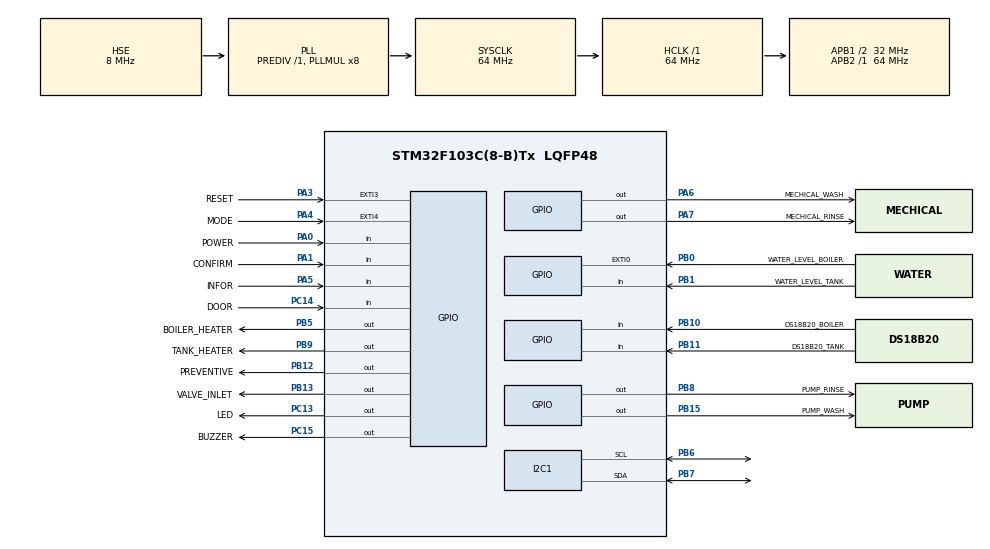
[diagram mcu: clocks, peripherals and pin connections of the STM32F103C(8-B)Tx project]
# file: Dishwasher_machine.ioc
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Mcu.Family=STM32F1
Mcu.Name=STM32F103C(8-B)Tx
Mcu.Package=LQFP48
NVIC.EXTI0_IRQn=true\:4\:0\:true\:false\:true\:true\:true\:true
NVIC.EXTI3_IRQn=true\:1\:0\:true\:false\:true\:true\:true\:true
NVIC.EXTI4_IRQn=true\:6\:0\:true\:false\:true\:true\:true\:true
NVIC.PriorityGroup=NVIC_PRIORITYGROUP_4
NVIC.TIM3_IRQn=true\:2\:0\:true\:false\:true\:true\:true\:true
PA0-WKUP.GPIO_Label=POWER
PA0-WKUP.GPIO_PuPd=GPIO_PULLUP
PA0-WKUP.Signal=GPIO_Input
PA1.GPIO_Label=CONFIRM
PA1.GPIO_PuPd=GPIO_PULLUP
PA1.Signal=GPIO_Input
PA13.Mode=Serial_Wire
PA13.Signal=SYS_JTMS-SWDIO
PA14.Mode=Serial_Wire
PA14.Signal=SYS_JTCK-SWCLK
PA3.GPIO_Label=RESET
PA3.GPIO_ModeDefaultEXTI=GPIO_MODE_IT_FALLING
PA3.GPIO_PuPd=GPIO_PULLUP
PA3.Signal=GPXTI3
PA4.GPIO_Label=MODE
PA4.GPIO_ModeDefaultEXTI=GPIO_MODE_IT_FALLING
PA4.GPIO_PuPd=GPIO_PULLUP
PA4.Signal=GPXTI4
PA5.GPIO_Label=INFOR
PA5.GPIO_PuPd=GPIO_PULLUP
PA5.Signal=GPIO_Input
PA6.GPIO_Label=MECHICAL_WASH
PA6.GPIO_PuPd=GPIO_PULLUP
PA6.Signal=GPIO_Output
PA7.GPIO_Label=MECHICAL_RINSE
PA7.GPIO_PuPd=GPIO_PULLUP
PA7.Signal=GPIO_Output
PB0.GPIO_Label=WATER_LEVEL_BOILER
PB0.GPIO_ModeDefaultEXTI=GPIO_MODE_IT_FALLING
PB0.GPIO_PuPd=GPIO_PULLUP
PB0.Signal=GPXTI0
PB1.GPIO_Label=WATER_LEVEL_TANK
PB1.GPIO_PuPd=GPIO_PULLUP
PB1.Signal=GPIO_Input
PB10.GPIO_Label=DS18B20_BOILER
PB10.GPIO_PuPd=GPIO_PULLUP
PB10.Signal=GPIO_Input
PB11.GPIO_Label=DS18B20_TANK
PB11.GPIO_PuPd=GPIO_PULLUP
PB11.Signal=GPIO_Input
PB12.GPIO_Label=PREVENTIVE
PB12.GPIO_PuPd=GPIO_PULLUP
PB12.PinState=GPIO_PIN_SET
PB12.Signal=GPIO_Output
PB13.GPIO_Label=VALVE_INLET
PB13.GPIO_PuPd=GPIO_PULLUP
PB13.PinState=GPIO_PIN_SET
PB13.Signal=GPIO_Output
PB15.GPIO_Label=PUMP_WASH
PB15.GPIO_PuPd=GPIO_PULLUP
PB15.PinState=GPIO_PIN_SET
PB15.Signal=GPIO_Output
PB5.GPIO_Label=BOILER_HEATER
PB5.GPIO_PuPd=GPIO_PULLUP
PB5.GPIO_Speed=GPIO_SPEED_FREQ_LOW
PB5.PinState=GPIO_PIN_SET
PB5.Signal=GPIO_Output
PB6.Mode=I2C
PB6.Signal=I2C1_SCL
PB7.Mode=I2C
PB7.Signal=I2C1_SDA
PB8.GPIO_Label=PUMP_RINSE
PB8.GPIO_PuPd=GPIO_PULLUP
PB8.GPIO_Speed=GPIO_SPEED_FREQ_LOW
PB8.PinState=GPIO_PIN_SET
PB8.Signal=GPIO_Output
PB9.GPIO_Label=TANK_HEATER
PB9.GPIO_PuPd=GPIO_PULLUP
PB9.PinState=GPIO_PIN_SET
PB9.Signal=GPIO_Output
PC13-TAMPER-RTC.GPIO_Label=LED
PC13-TAMPER-RTC.GPIO_PuPd=GPIO_PULLUP
PC13-TAMPER-RTC.PinState=GPIO_PIN_SET
PC13-TAMPER-RTC.Signal=GPIO_Output
PC14-OSC32_IN.GPIO_Label=DOOR
PC14-OSC32_IN.GPIO_PuPd=GPIO_PULLUP
PC14-OSC32_IN.Signal=GPIO_Input
PC15-OSC32_OUT.GPIO_Label=BUZZER
PC15-OSC32_OUT.GPIO_PuPd=GPIO_PULLUP
PC15-OSC32_OUT.Signal=GPIO_Output
PD0-OSC_IN.Mode=HSE-External-Oscillator
PD0-OSC_IN.Signal=RCC_OSC_IN
PD1-OSC_OUT.Mode=HSE-External-Oscillator
PD1-OSC_OUT.Signal=RCC_OSC_OUT
ProjectManager.HeapSize=0x200
ProjectManager.StackSize=0x400
ProjectManager.TargetToolchain=MDK-ARM V5.32
RCC.AHBFreq_Value=64000000
RCC.APB1CLKDivider=RCC_HCLK_DIV2
RCC.APB1Freq_Value=32000000
RCC.APB1TimFreq_Value=64000000
RCC.APB2Freq_Value=64000000
RCC.APB2TimFreq_Value=64000000
RCC.HCLKFreq_Value=64000000
RCC.PLLMUL=RCC_PLL_MUL8
RCC.PLLSourceVirtual=RCC_PLLSOURCE_HSE
RCC.SYSCLKFreq_VALUE=64000000
RCC.SYSCLKSource=RCC_SYSCLKSOURCE_PLLCLK
RCC.USBFreq_Value=64000000
TIM1.Period=65535-1
TIM1.Prescaler=64-1
TIM3.Period=2000-1
TIM3.Prescaler=64000-1
VP_TIM1_VS_ClockSourceINT.Mode=Internal
VP_TIM3_VS_ClockSourceINT.Mode=Internal
board=custom

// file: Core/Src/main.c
/* USER CODE BEGIN Header */
/* USER CODE END Header */
#include "main.h"

/* USER CODE BEGIN Includes */
#include "i2c-lcd.h"
#include "stdio.h"
#include "Funtion.h"

/* USER CODE END Includes */

I2C_HandleTypeDef hi2c1;
TIM_HandleTypeDef htim1;
TIM_HandleTypeDef htim3;
uint8_t 		power_press =0;
float 	volatile 	Temperature_boiler;
float 	volatile 	Temperature_tank = 0;
uint8_t 	volatile 	Presence = 0;
uint8_t 	volatile 	Temp_byte1, Temp_byte2;
uint16_t volatile 	TEMP;
uint8_t 	volatile 	BOILER_FULL=0;
uint8_t 	volatile 	TANK_FULL=0;
uint8_t 	volatile 	DOOR =1;
uint8_t 	volatile 	MODE =0;
uint8_t 	const 	Temp_Std_Wash =20;
uint8_t 	const 	Temp_Std_Rinse =20;
uint8_t 	const 	Temperature_max =100;
uint8_t count =0;
uint8_t a=0;

void SystemClock_Config(void);
static void MX_GPIO_Init(void);
static void MX_I2C1_Init(void);
static void MX_TIM1_Init(void);
static void MX_TIM3_Init(void);

int main(void)
{

  /* MCU Configuration--------------------------------------------------------*/

  /* Reset of all peripherals, Initializes the Flash interface and the Systick. */
  HAL_Init();

  /* Configure the system clock */
  SystemClock_Config();

  /* Initialize all configured peripherals */
  MX_GPIO_Init();
  MX_I2C1_Init();
  MX_TIM1_Init();
  MX_TIM3_Init();

  /* Infinite loop */
	while(1){
CHECK_PRESS_POWER_BUTTON();
SET_BUZZER();
INSPECT_WATER_LEVEL_OF_BOILER();
INSPECT_TEMPORATURE_OF_BOILER(Temp_Std_Wash);
READY();
CLOSE_DOOR_TO_WASH(Temp_Std_Wash,Temp_Std_Rinse);
SELECT_MODE(Temp_Std_Wash,Temp_Std_Rinse);
}
}
void SystemClock_Config(void)
{
  RCC_OscInitTypeDef RCC_OscInitStruct = {0};
  RCC_ClkInitTypeDef RCC_ClkInitStruct = {0};

  /** Initializes the RCC Oscillators according to the specified parameters
  * in the RCC_OscInitTypeDef structure.
  */
  RCC_OscInitStruct.OscillatorType = RCC_OSCILLATORTYPE_HSE;
  RCC_OscInitStruct.HSEState = RCC_HSE_ON;
  RCC_OscInitStruct.HSEPredivValue = RCC_HSE_PREDIV_DIV1;
  RCC_OscInitStruct.HSIState = RCC_HSI_ON;
  RCC_OscInitStruct.PLL.PLLState = RCC_PLL_ON;
  RCC_OscInitStruct.PLL.PLLSource = RCC_PLLSOURCE_HSE;
  RCC_OscInitStruct.PLL.PLLMUL = RCC_PLL_MUL8;
  if (HAL_RCC_OscConfig(&RCC_OscInitStruct) != HAL_OK)
  {
    Error_Handler();
  }

  /** Initializes the CPU, AHB and APB buses clocks
  */
  RCC_ClkInitStruct.ClockType = RCC_CLOCKTYPE_HCLK|RCC_CLOCKTYPE_SYSCLK
                              |RCC_CLOCKTYPE_PCLK1|RCC_CLOCKTYPE_PCLK2;
  RCC_ClkInitStruct.SYSCLKSource = RCC_SYSCLKSOURCE_PLLCLK;
  RCC_ClkInitStruct.AHBCLKDivider = RCC_SYSCLK_DIV1;
  RCC_ClkInitStruct.APB1CLKDivider = RCC_HCLK_DIV2;
  RCC_ClkInitStruct.APB2CLKDivider = RCC_HCLK_DIV1;

  if (HAL_RCC_ClockConfig(&RCC_ClkInitStruct, FLASH_LATENCY_2) != HAL_OK)
  {
    Error_Handler();
  }
}

static void MX_I2C1_Init(void)
{

  hi2c1.Instance = I2C1;
  hi2c1.Init.ClockSpeed = 100000;
  hi2c1.Init.DutyCycle = I2C_DUTYCYCLE_2;
  hi2c1.Init.OwnAddress1 = 0;
  hi2c1.Init.AddressingMode = I2C_ADDRESSINGMODE_7BIT;
  hi2c1.Init.DualAddressMode = I2C_DUALADDRESS_DISABLE;
  hi2c1.Init.OwnAddress2 = 0;
  hi2c1.Init.GeneralCallMode = I2C_GENERALCALL_DISABLE;
  hi2c1.Init.NoStretchMode = I2C_NOSTRETCH_DISABLE;
  if (HAL_I2C_Init(&hi2c1) != HAL_OK)
  {
    Error_Handler();
  }

}

static void MX_TIM1_Init(void)
{

  TIM_ClockConfigTypeDef sClockSourceConfig = {0};
  TIM_MasterConfigTypeDef sMasterConfig = {0};

  htim1.Instance = TIM1;
  htim1.Init.Prescaler = 64-1;
  htim1.Init.CounterMode = TIM_COUNTERMODE_UP;
  htim1.Init.Period = 65535-1;
  htim1.Init.ClockDivision = TIM_CLOCKDIVISION_DIV1;
  htim1.Init.RepetitionCounter = 0;
  htim1.Init.AutoReloadPreload = TIM_AUTORELOAD_PRELOAD_DISABLE;
  if (HAL_TIM_Base_Init(&htim1) != HAL_OK)
  {
    Error_Handler();
  }
  sClockSourceConfig.ClockSource = TIM_CLOCKSOURCE_INTERNAL;
  if (HAL_TIM_ConfigClockSource(&htim1, &sClockSourceConfig) != HAL_OK)
  {
    Error_Handler();
  }
  sMasterConfig.MasterOutputTrigger = TIM_TRGO_RESET;
  sMasterConfig.MasterSlaveMode = TIM_MASTERSLAVEMODE_DISABLE;
  if (HAL_TIMEx_MasterConfigSynchronization(&htim1, &sMasterConfig) != HAL_OK)
  {
    Error_Handler();
  }

}

static void MX_TIM3_Init(void)
{

  TIM_ClockConfigTypeDef sClockSourceConfig = {0};
  TIM_MasterConfigTypeDef sMasterConfig = {0};

  htim3.Instance = TIM3;
  htim3.Init.Prescaler = 64000-1;
  htim3.Init.CounterMode = TIM_COUNTERMODE_UP;
  htim3.Init.Period = 2000-1;
  htim3.Init.ClockDivision = TIM_CLOCKDIVISION_DIV1;
  htim3.Init.AutoReloadPreload = TIM_AUTORELOAD_PRELOAD_DISABLE;
  if (HAL_TIM_Base_Init(&htim3) != HAL_OK)
  {
    Error_Handler();
  }
  sClockSourceConfig.ClockSource = TIM_CLOCKSOURCE_INTERNAL;
  if (HAL_TIM_ConfigClockSource(&htim3, &sClockSourceConfig) != HAL_OK)
  {
    Error_Handler();
  }
  sMasterConfig.MasterOutputTrigger = TIM_TRGO_RESET;
  sMasterConfig.MasterSlaveMode = TIM_MASTERSLAVEMODE_DISABLE;
  if (HAL_TIMEx_MasterConfigSynchronization(&htim3, &sMasterConfig) != HAL_OK)
  {
    Error_Handler();
  }

}

static void MX_GPIO_Init(void)
{
  GPIO_InitTypeDef GPIO_InitStruct = {0};

  /* GPIO Ports Clock Enable */
  __HAL_RCC_GPIOC_CLK_ENABLE();
  __HAL_RCC_GPIOD_CLK_ENABLE();
  __HAL_RCC_GPIOA_CLK_ENABLE();
  __HAL_RCC_GPIOB_CLK_ENABLE();

  /*Configure GPIO pin Output Level */
  HAL_GPIO_WritePin(LED_GPIO_Port, LED_Pin, GPIO_PIN_SET);

  /*Configure GPIO pin Output Level */
  HAL_GPIO_WritePin(BUZZER_GPIO_Port, BUZZER_Pin, GPIO_PIN_RESET);

  /*Configure GPIO pin Output Level */
  HAL_GPIO_WritePin(GPIOA, MECHICAL_WASH_Pin|MECHICAL_RINSE_Pin, GPIO_PIN_RESET);

  /*Configure GPIO pin Output Level */
  HAL_GPIO_WritePin(GPIOB, PREVENTIVE_Pin|VALVE_INLET_Pin|PUMP_WASH_Pin|BOILER_HEATER_Pin
                          |PUMP_RINSE_Pin|TANK_HEATER_Pin, GPIO_PIN_SET);

  /*Configure GPIO pins : LED_Pin BUZZER_Pin */
  GPIO_InitStruct.Pin = LED_Pin|BUZZER_Pin;
  GPIO_InitStruct.Mode = GPIO_MODE_OUTPUT_PP;
  GPIO_InitStruct.Pull = GPIO_PULLUP;
  GPIO_InitStruct.Speed = GPIO_SPEED_FREQ_LOW;
  HAL_GPIO_Init(GPIOC, &GPIO_InitStruct);

  /*Configure GPIO pin : DOOR_Pin */
  GPIO_InitStruct.Pin = DOOR_Pin;
  GPIO_InitStruct.Mode = GPIO_MODE_INPUT;
  GPIO_InitStruct.Pull = GPIO_PULLUP;
  HAL_GPIO_Init(DOOR_GPIO_Port, &GPIO_InitStruct);

  /*Configure GPIO pins : POWER_Pin CONFIRM_Pin INFOR_Pin */
  GPIO_InitStruct.Pin = POWER_Pin|CONFIRM_Pin|INFOR_Pin;
  GPIO_InitStruct.Mode = GPIO_MODE_INPUT;
  GPIO_InitStruct.Pull = GPIO_PULLUP;
  HAL_GPIO_Init(GPIOA, &GPIO_InitStruct);

  /*Configure GPIO pins : RESET_Pin MODE_Pin */
  GPIO_InitStruct.Pin = RESET_Pin|MODE_Pin;
  GPIO_InitStruct.Mode = GPIO_MODE_IT_FALLING;
  GPIO_InitStruct.Pull = GPIO_PULLUP;
  HAL_GPIO_Init(GPIOA, &GPIO_InitStruct);

  /*Configure GPIO pins : MECHICAL_WASH_Pin MECHICAL_RINSE_Pin */
  GPIO_InitStruct.Pin = MECHICAL_WASH_Pin|MECHICAL_RINSE_Pin;
  GPIO_InitStruct.Mode = GPIO_MODE_OUTPUT_PP;
  GPIO_InitStruct.Pull = GPIO_PULLUP;
  GPIO_InitStruct.Speed = GPIO_SPEED_FREQ_LOW;
  HAL_GPIO_Init(GPIOA, &GPIO_InitStruct);

  /*Configure GPIO pin : WATER_LEVEL_BOILER_Pin */
  GPIO_InitStruct.Pin = WATER_LEVEL_BOILER_Pin;
  GPIO_InitStruct.Mode = GPIO_MODE_IT_FALLING;
  GPIO_InitStruct.Pull = GPIO_PULLUP;
  HAL_GPIO_Init(WATER_LEVEL_BOILER_GPIO_Port, &GPIO_InitStruct);

  /*Configure GPIO pins : WATER_LEVEL_TANK_Pin DS18B20_BOILER_Pin DS18B20_TANK_Pin */
  GPIO_InitStruct.Pin = WATER_LEVEL_TANK_Pin|DS18B20_BOILER_Pin|DS18B20_TANK_Pin;
  GPIO_InitStruct.Mode = GPIO_MODE_INPUT;
  GPIO_InitStruct.Pull = GPIO_PULLUP;
  HAL_GPIO_Init(GPIOB, &GPIO_InitStruct);

  /*Configure GPIO pins : PREVENTIVE_Pin VALVE_INLET_Pin PUMP_WASH_Pin BOILER_HEATER_Pin
                           PUMP_RINSE_Pin TANK_HEATER_Pin */
  GPIO_InitStruct.Pin = PREVENTIVE_Pin|VALVE_INLET_Pin|PUMP_WASH_Pin|BOILER_HEATER_Pin
                          |PUMP_RINSE_Pin|TANK_HEATER_Pin;
  GPIO_InitStruct.Mode = GPIO_MODE_OUTPUT_PP;
  GPIO_InitStruct.Pull = GPIO_PULLUP;
  GPIO_InitStruct.Speed = GPIO_SPEED_FREQ_LOW;
  HAL_GPIO_Init(GPIOB, &GPIO_InitStruct);

  /* EXTI interrupt init*/
  //HAL_NVIC_SetPriority(EXTI0_IRQn, 4, 0);
  HAL_NVIC_EnableIRQ(EXTI0_IRQn);

  HAL_NVIC_SetPriority(EXTI3_IRQn, 1, 0);
  HAL_NVIC_EnableIRQ(EXTI3_IRQn);

  //HAL_NVIC_SetPriority(EXTI4_IRQn, 6, 0);
  HAL_NVIC_EnableIRQ(EXTI4_IRQn);

}

void Error_Handler(void)
{
}
